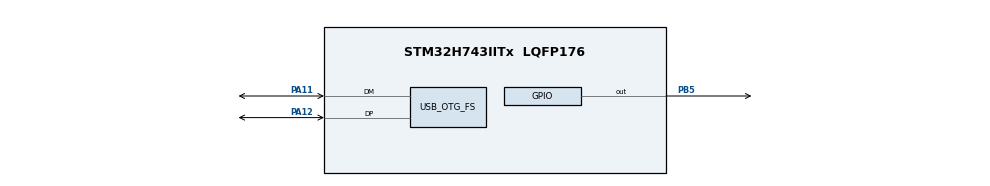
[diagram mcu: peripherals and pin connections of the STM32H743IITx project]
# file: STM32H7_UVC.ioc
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Mcu.Family=STM32H7
Mcu.Name=STM32H743IITx
Mcu.Package=LQFP176
Mcu.UserConstants=LTDC_BUFF_ADDR,0XC0000000;PIXELS_W,800;PIXELS_H,480;PIXELS_DIR,0
NVIC.OTG_FS_IRQn=true\:0\:0\:false\:false\:true\:false\:true\:true
NVIC.PriorityGroup=NVIC_PRIORITYGROUP_4
PA11.Mode=Device_Only
PA11.Signal=USB_OTG_FS_DM
PA12.Mode=Device_Only
PA12.Signal=USB_OTG_FS_DP
PB5.Signal=GPIO_Output
PG11.GPIO_Mode=GPIO_MODE_AF_PP
PG11.GPIO_PuPd=GPIO_NOPULL
PG11.GPIO_Speed=GPIO_SPEED_FREQ_LOW
PG11.Signal=LTDC_B3
PH0-OSC_IN\ (PH0).Mode=HSE-External-Oscillator
PH0-OSC_IN\ (PH0).Signal=RCC_OSC_IN
PH1-OSC_OUT\ (PH1).Mode=HSE-External-Oscillator
PH1-OSC_OUT\ (PH1).Signal=RCC_OSC_OUT
PH10.GPIO_Mode=GPIO_MODE_AF_PP
PH10.GPIO_PuPd=GPIO_NOPULL
PH10.GPIO_Speed=GPIO_SPEED_FREQ_LOW
PH10.Signal=LTDC_R4
PH11.GPIO_Mode=GPIO_MODE_AF_PP
PH11.GPIO_PuPd=GPIO_NOPULL
PH11.GPIO_Speed=GPIO_SPEED_FREQ_LOW
PH11.Signal=LTDC_R5
PH12.GPIO_Mode=GPIO_MODE_AF_PP
PH12.GPIO_PuPd=GPIO_NOPULL
PH12.GPIO_Speed=GPIO_SPEED_FREQ_LOW
PH12.Signal=LTDC_R6
PH13.GPIO_Mode=GPIO_MODE_AF_PP
PH13.GPIO_PuPd=GPIO_NOPULL
PH13.GPIO_Speed=GPIO_SPEED_FREQ_LOW
PH13.Signal=LTDC_G2
PH14.GPIO_Mode=GPIO_MODE_AF_PP
PH14.GPIO_PuPd=GPIO_NOPULL
PH14.GPIO_Speed=GPIO_SPEED_FREQ_LOW
PH14.Signal=LTDC_G3
PH15.GPIO_Mode=GPIO_MODE_AF_PP
PH15.GPIO_PuPd=GPIO_NOPULL
PH15.GPIO_Speed=GPIO_SPEED_FREQ_LOW
PH15.Signal=LTDC_G4
PH9.GPIO_Mode=GPIO_MODE_AF_PP
PH9.GPIO_PuPd=GPIO_NOPULL
PH9.GPIO_Speed=GPIO_SPEED_FREQ_LOW
PH9.Signal=LTDC_R3
PI0.GPIO_Mode=GPIO_MODE_AF_PP
PI0.GPIO_PuPd=GPIO_NOPULL
PI0.GPIO_Speed=GPIO_SPEED_FREQ_LOW
PI0.Signal=LTDC_G5
PI1.GPIO_Mode=GPIO_MODE_AF_PP
PI1.GPIO_PuPd=GPIO_NOPULL
PI1.GPIO_Speed=GPIO_SPEED_FREQ_LOW
PI1.Signal=LTDC_G6
PI4.GPIO_Mode=GPIO_MODE_AF_PP
PI4.GPIO_PuPd=GPIO_NOPULL
PI4.GPIO_Speed=GPIO_SPEED_FREQ_LOW
PI4.Signal=LTDC_B4
PI5.GPIO_Mode=GPIO_MODE_AF_PP
PI5.GPIO_PuPd=GPIO_NOPULL
PI5.GPIO_Speed=GPIO_SPEED_FREQ_LOW
PI5.Signal=LTDC_B5
PI6.GPIO_Mode=GPIO_MODE_AF_PP
PI6.GPIO_PuPd=GPIO_NOPULL
PI6.GPIO_Speed=GPIO_SPEED_FREQ_LOW
PI6.Signal=LTDC_B6
PI7.GPIO_Mode=GPIO_MODE_AF_PP
PI7.GPIO_PuPd=GPIO_NOPULL
PI7.GPIO_Speed=GPIO_SPEED_FREQ_LOW
PI7.Signal=LTDC_B7
ProjectManager.HeapSize=0x200
ProjectManager.StackSize=0x400
ProjectManager.TargetToolchain=MDK-ARM V5.32
RCC.ADCFreq_Value=50390625
RCC.APB1Freq_Value=120000000
RCC.APB2Freq_Value=120000000
RCC.APB3Freq_Value=120000000
RCC.APB4Freq_Value=120000000
RCC.CortexFreq_Value=480000000
RCC.D1PPRE=RCC_APB3_DIV2
RCC.D2PPRE1=RCC_APB1_DIV2
RCC.D2PPRE2=RCC_APB2_DIV2
RCC.D3PPRE=RCC_APB4_DIV2
RCC.DIVM1=5
RCC.DIVM3=5
RCC.DIVN1=192
RCC.DIVN3=192
RCC.DIVQ3=20
RCC.DIVR3=25
RCC.HCLKFreq_Value=240000000
RCC.HPRE=RCC_HCLK_DIV2
RCC.PLL2FRACN=0
RCC.PLL3FRACN=0
RCC.PLLFRACN=0
RCC.PLLSourceVirtual=RCC_PLLSOURCE_HSE
RCC.SYSCLKFreq_VALUE=480000000
RCC.SYSCLKSource=RCC_SYSCLKSOURCE_PLLCLK
RCC.USBCLockSelection=RCC_USBCLKSOURCE_HSI48
RCC.USBFreq_Value=48000000
USB_DEVICE.CLASS_NAME_FS=CDC
USB_DEVICE.VirtualMode-CDC_FS=Cdc
USB_DEVICE.VirtualModeFS=Cdc_FS
USB_OTG_FS.Sof_enable=ENABLE
USB_OTG_FS.VirtualMode=Device_Only
USB_OTG_FS.dma_enable=ENABLE
USB_OTG_FS.lpm_enable=DISABLE
VP_USB_DEVICE_VS_USB_DEVICE_CDC_FS.Mode=CDC_FS
board=custom

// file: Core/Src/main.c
/* USER CODE BEGIN Header */
/**
  ******************************************************************************
  * @file           : main.c
  * @brief          : Main program body
  ******************************************************************************
  * @attention
  *
  * Copyright (c) 2023 STMicroelectronics.
  * All rights reserved.
  *
  * This software is licensed under terms that can be found in the LICENSE file
  * in the root directory of this software component.
  * If no LICENSE file comes with this software, it is provided AS-IS.
  *
  ******************************************************************************
  */
/* USER CODE END Header */
#include "main.h"
#include "usb_device.h"

/* USER CODE BEGIN Includes */
#include "UserMain.h"
/* USER CODE END Includes */

void SystemClock_Config(void);
static void MX_GPIO_Init(void);

int main(void)
{

  /* MCU Configuration--------------------------------------------------------*/

  /* Reset of all peripherals, Initializes the Flash interface and the Systick. */
  HAL_Init();

  /* Configure the system clock */
  SystemClock_Config();

  /* USER CODE BEGIN SysInit */
	//Stm32_Clock_Init(192,5,2,4);  		    //????,400Mhz
  /* USER CODE END SysInit */

  /* Initialize all configured peripherals */
  //MX_GPIO_Init();
 // MX_USB_DEVICE_Init();
  /* USER CODE BEGIN 2 */
    UserSysInit();
    UserConfigInit();
  /* USER CODE END 2 */

  /* Infinite loop */
  /* USER CODE BEGIN WHILE */
  while (1)
  {
     UserLoop();
    /* USER CODE END WHILE */

  }
}

void SystemClock_Config(void)
{
  RCC_OscInitTypeDef RCC_OscInitStruct = {0};
  RCC_ClkInitTypeDef RCC_ClkInitStruct = {0};

  /** Supply configuration update enable
  */
  HAL_PWREx_ConfigSupply(PWR_LDO_SUPPLY);

  /** Configure the main internal regulator output voltage
  */
  __HAL_PWR_VOLTAGESCALING_CONFIG(PWR_REGULATOR_VOLTAGE_SCALE1);

  while(!__HAL_PWR_GET_FLAG(PWR_FLAG_VOSRDY)) {}

  __HAL_RCC_SYSCFG_CLK_ENABLE();
  __HAL_PWR_VOLTAGESCALING_CONFIG(PWR_REGULATOR_VOLTAGE_SCALE0);

  while(!__HAL_PWR_GET_FLAG(PWR_FLAG_VOSRDY)) {}

  /** Initializes the RCC Oscillators according to the specified parameters
  * in the RCC_OscInitTypeDef structure.
  */
  RCC_OscInitStruct.OscillatorType = RCC_OSCILLATORTYPE_HSI48|RCC_OSCILLATORTYPE_HSE;
  RCC_OscInitStruct.HSEState = RCC_HSE_ON;
  RCC_OscInitStruct.HSI48State = RCC_HSI48_ON;
  RCC_OscInitStruct.PLL.PLLState = RCC_PLL_ON;
  RCC_OscInitStruct.PLL.PLLSource = RCC_PLLSOURCE_HSE;
  RCC_OscInitStruct.PLL.PLLM = 5;
  RCC_OscInitStruct.PLL.PLLN = 192;
  RCC_OscInitStruct.PLL.PLLP = 2;
  RCC_OscInitStruct.PLL.PLLQ = 2;
  RCC_OscInitStruct.PLL.PLLR = 2;
  RCC_OscInitStruct.PLL.PLLRGE = RCC_PLL1VCIRANGE_2;
  RCC_OscInitStruct.PLL.PLLVCOSEL = RCC_PLL1VCOWIDE;
  RCC_OscInitStruct.PLL.PLLFRACN = 0;
  if (HAL_RCC_OscConfig(&RCC_OscInitStruct) != HAL_OK)
  {
    Error_Handler();
  }

  /** Initializes the CPU, AHB and APB buses clocks
  */
  RCC_ClkInitStruct.ClockType = RCC_CLOCKTYPE_HCLK|RCC_CLOCKTYPE_SYSCLK
                              |RCC_CLOCKTYPE_PCLK1|RCC_CLOCKTYPE_PCLK2
                              |RCC_CLOCKTYPE_D3PCLK1|RCC_CLOCKTYPE_D1PCLK1;
  RCC_ClkInitStruct.SYSCLKSource = RCC_SYSCLKSOURCE_PLLCLK;
  RCC_ClkInitStruct.SYSCLKDivider = RCC_SYSCLK_DIV1;
  RCC_ClkInitStruct.AHBCLKDivider = RCC_HCLK_DIV2;
  RCC_ClkInitStruct.APB3CLKDivider = RCC_APB3_DIV2;
  RCC_ClkInitStruct.APB1CLKDivider = RCC_APB1_DIV2;
  RCC_ClkInitStruct.APB2CLKDivider = RCC_APB2_DIV2;
  RCC_ClkInitStruct.APB4CLKDivider = RCC_APB4_DIV2;

  if (HAL_RCC_ClockConfig(&RCC_ClkInitStruct, FLASH_LATENCY_4) != HAL_OK)
  {
    Error_Handler();
  }
}

static void MX_GPIO_Init(void)
{
  GPIO_InitTypeDef GPIO_InitStruct = {0};

  /* GPIO Ports Clock Enable */
  __HAL_RCC_GPIOH_CLK_ENABLE();
  __HAL_RCC_GPIOA_CLK_ENABLE();
  __HAL_RCC_GPIOI_CLK_ENABLE();
  __HAL_RCC_GPIOG_CLK_ENABLE();
  __HAL_RCC_GPIOB_CLK_ENABLE();

  /*Configure GPIO pin Output Level */
  HAL_GPIO_WritePin(GPIOB, GPIO_PIN_5, GPIO_PIN_RESET);

  /*Configure GPIO pins : PH9 PH10 PH11 PH12
                           PH13 PH14 PH15 */
  GPIO_InitStruct.Pin = GPIO_PIN_9|GPIO_PIN_10|GPIO_PIN_11|GPIO_PIN_12
                          |GPIO_PIN_13|GPIO_PIN_14|GPIO_PIN_15;
  GPIO_InitStruct.Mode = GPIO_MODE_AF_PP;
  GPIO_InitStruct.Pull = GPIO_NOPULL;
  GPIO_InitStruct.Speed = GPIO_SPEED_FREQ_LOW;
  GPIO_InitStruct.Alternate = GPIO_AF14_LTDC;
  HAL_GPIO_Init(GPIOH, &GPIO_InitStruct);

  /*Configure GPIO pins : PI0 PI1 PI4 PI5
                           PI6 PI7 */
  GPIO_InitStruct.Pin = GPIO_PIN_0|GPIO_PIN_1|GPIO_PIN_4|GPIO_PIN_5
                          |GPIO_PIN_6|GPIO_PIN_7;
  GPIO_InitStruct.Mode = GPIO_MODE_AF_PP;
  GPIO_InitStruct.Pull = GPIO_NOPULL;
  GPIO_InitStruct.Speed = GPIO_SPEED_FREQ_LOW;
  GPIO_InitStruct.Alternate = GPIO_AF14_LTDC;
  HAL_GPIO_Init(GPIOI, &GPIO_InitStruct);

  /*Configure GPIO pin : PG11 */
  GPIO_InitStruct.Pin = GPIO_PIN_11;
  GPIO_InitStruct.Mode = GPIO_MODE_AF_PP;
  GPIO_InitStruct.Pull = GPIO_NOPULL;
  GPIO_InitStruct.Speed = GPIO_SPEED_FREQ_LOW;
  GPIO_InitStruct.Alternate = GPIO_AF14_LTDC;
  HAL_GPIO_Init(GPIOG, &GPIO_InitStruct);

  /*Configure GPIO pin : PB5 */
  GPIO_InitStruct.Pin = GPIO_PIN_5;
  GPIO_InitStruct.Mode = GPIO_MODE_OUTPUT_PP;
  GPIO_InitStruct.Pull = GPIO_NOPULL;
  GPIO_InitStruct.Speed = GPIO_SPEED_FREQ_LOW;
  HAL_GPIO_Init(GPIOB, &GPIO_InitStruct);

}

void Error_Handler(void)
{
  /* USER CODE BEGIN Error_Handler_Debug */
  /* User can add his own implementation to report the HAL error return state */
  __disable_irq();
	UserErrorHandler();
  while (1)
  {
  }
  /* USER CODE END Error_Handler_Debug */
}
